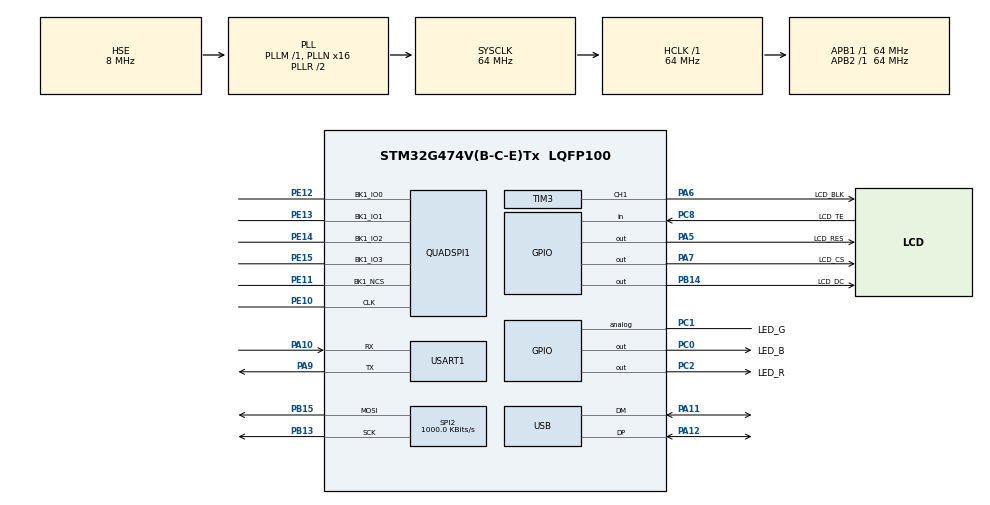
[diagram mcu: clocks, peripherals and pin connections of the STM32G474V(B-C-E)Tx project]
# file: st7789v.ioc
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Dma.Request0=SPI2_TX
Dma.SPI2_TX.0.Direction=DMA_MEMORY_TO_PERIPH
Dma.SPI2_TX.0.EventEnable=DISABLE
Dma.SPI2_TX.0.Instance=DMA1_Channel1
Dma.SPI2_TX.0.MemDataAlignment=DMA_MDATAALIGN_BYTE
Dma.SPI2_TX.0.MemInc=DMA_MINC_ENABLE
Dma.SPI2_TX.0.Mode=DMA_NORMAL
Dma.SPI2_TX.0.PeriphDataAlignment=DMA_PDATAALIGN_BYTE
Dma.SPI2_TX.0.PeriphInc=DMA_PINC_DISABLE
Dma.SPI2_TX.0.Polarity=HAL_DMAMUX_REQ_GEN_RISING
Dma.SPI2_TX.0.Priority=DMA_PRIORITY_LOW
Dma.SPI2_TX.0.RequestNumber=1
Dma.SPI2_TX.0.SignalID=NONE
Dma.SPI2_TX.0.SyncEnable=DISABLE
Dma.SPI2_TX.0.SyncPolarity=HAL_DMAMUX_SYNC_NO_EVENT
Dma.SPI2_TX.0.SyncRequestNumber=1
Dma.SPI2_TX.0.SyncSignalID=NONE
Mcu.Family=STM32G4
Mcu.Name=STM32G474V(B-C-E)Tx
Mcu.Package=LQFP100
NVIC.DMA1_Channel1_IRQn=true\:0\:0\:false\:false\:true\:false\:true\:true
NVIC.PriorityGroup=NVIC_PRIORITYGROUP_4
NVIC.USB_LP_IRQn=true\:0\:0\:false\:false\:true\:false\:true\:true
PA10.Mode=Asynchronous
PA10.Signal=USART1_RX
PA11.Mode=Device
PA11.Signal=USB_DM
PA12.Mode=Device
PA12.Signal=USB_DP
PA13.Mode=Serial_Wire
PA13.Signal=SYS_JTMS-SWDIO
PA14.Mode=Serial_Wire
PA14.Signal=SYS_JTCK-SWCLK
PA5.GPIO_Label=LCD_RES
PA5.Signal=GPIO_Output
PA6.GPIO_Label=LCD_BLK
PA6.Signal=S_TIM3_CH1
PA7.GPIO_Label=LCD_CS
PA7.Signal=GPIO_Output
PA9.Mode=Asynchronous
PA9.Signal=USART1_TX
PB13.Mode=TX_Only_Simplex_Unidirect_Master
PB13.Signal=SPI2_SCK
PB14.GPIO_Label=LCD_DC
PB14.Signal=GPIO_Output
PB15.Mode=TX_Only_Simplex_Unidirect_Master
PB15.Signal=SPI2_MOSI
PC0.GPIO_Label=LED_B
PC0.Signal=GPIO_Output
PC1.GPIO_Label=LED_G
PC1.Signal=GPIO_Analog
PC14-OSC32_IN.Mode=LSE-External-Oscillator
PC14-OSC32_IN.Signal=RCC_OSC32_IN
PC15-OSC32_OUT.Mode=LSE-External-Oscillator
PC15-OSC32_OUT.Signal=RCC_OSC32_OUT
PC2.GPIO_Label=LED_R
PC2.Signal=GPIO_Output
PC8.GPIO_Label=LCD_TE
PC8.GPIO_PuPd=GPIO_NOPULL
PC8.Signal=GPIO_Input
PE10.Mode=Single Bank 1
PE10.Signal=QUADSPI1_CLK
PE11.Mode=Single Bank 1
PE11.Signal=QUADSPI1_BK1_NCS
PE12.Mode=Single Bank 1
PE12.Signal=QUADSPI1_BK1_IO0
PE13.Mode=Single Bank 1
PE13.Signal=QUADSPI1_BK1_IO1
PE14.Mode=Single Bank 1
PE14.Signal=QUADSPI1_BK1_IO2
PE15.Mode=Single Bank 1
PE15.Signal=QUADSPI1_BK1_IO3
PF0-OSC_IN.Mode=HSE-External-Oscillator
PF0-OSC_IN.Signal=RCC_OSC_IN
PF1-OSC_OUT.Mode=HSE-External-Oscillator
PF1-OSC_OUT.Signal=RCC_OSC_OUT
ProjectManager.HeapSize=0x200
ProjectManager.StackSize=0x400
ProjectManager.TargetToolchain=STM32CubeIDE
RCC.ADC12Freq_Value=64000000
RCC.ADC345Freq_Value=64000000
RCC.AHBFreq_Value=64000000
RCC.APB1Freq_Value=64000000
RCC.APB1TimFreq_Value=64000000
RCC.APB2Freq_Value=64000000
RCC.APB2TimFreq_Value=64000000
RCC.CK48CLockSelection=RCC_USBCLKSOURCE_HSI48
RCC.CortexFreq_Value=64000000
RCC.EXTERNAL_CLOCK_VALUE=12288000
RCC.EnableCSSLSE=true
RCC.EnbaleCSS=true
RCC.HCLKFreq_Value=64000000
RCC.HSE_VALUE=8000000
RCC.HSI48_VALUE=48000000
RCC.HSI_VALUE=16000000
RCC.PLLN=16
RCC.PLLSourceVirtual=RCC_PLLSOURCE_HSE
RCC.RTCClockSelection=RCC_RTCCLKSOURCE_LSE
RCC.SYSCLKFreq_VALUE=64000000
RCC.SYSCLKSource=RCC_SYSCLKSOURCE_PLLCLK
RCC.USBFreq_Value=48000000
RCC.VCOOutputFreq_Value=128000000
SH.S_TIM3_CH1.0=TIM3_CH1,PWM Generation1 CH1
SPI2.BaudRatePrescaler=SPI_BAUDRATEPRESCALER_64
SPI2.CLKPhase=SPI_PHASE_2EDGE
SPI2.CLKPolarity=SPI_POLARITY_HIGH
SPI2.CalculateBaudRate=1000.0 KBits/s
SPI2.DataSize=SPI_DATASIZE_8BIT
SPI2.Direction=SPI_DIRECTION_2LINES
SPI2.Mode=SPI_MODE_MASTER
SPI2.VirtualType=VM_MASTER
TIM3.Channel-PWM\ Generation1\ CH1=TIM_CHANNEL_1
TIM3.PulseNoDither_1=32768 - 1
USART1.VirtualMode-Asynchronous=VM_ASYNC
USB_DEVICE.CLASS_NAME_FS=CDC
USB_DEVICE.VirtualMode=Cdc
USB_DEVICE.VirtualModeFS=Cdc_FS
VP_RTC_VS_RTC_Activate.Mode=RTC_Enabled
VP_SYS_VS_DBSignals.Mode=DisableDeadBatterySignals
VP_USB_DEVICE_VS_USB_DEVICE_CDC_FS.Mode=CDC_FS
board=custom

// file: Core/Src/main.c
/* USER CODE BEGIN Header */
/**
  ******************************************************************************
  * @file           : main.c
  * @brief          : Main program body
  ******************************************************************************
  * @attention
  *
  * Copyright (c) 2026 STMicroelectronics.
  * All rights reserved.
  *
  * This software is licensed under terms that can be found in the LICENSE file
  * in the root directory of this software component.
  * If no LICENSE file comes with this software, it is provided AS-IS.
  *
  ******************************************************************************
  */
/* USER CODE END Header */
#include "main.h"
#include "dma.h"
#include "quadspi.h"
#include "rtc.h"
#include "spi.h"
#include "tim.h"
#include "usart.h"
#include "usb_device.h"
#include "gpio.h"

void SystemClock_Config(void);
/* USER CODE BEGIN PFP */
#ifdef __GNUC__
#define PUTCHAR_PROTOTYPE int __io_putchar(int ch)
#else
#define PUTCHAR_PROTOTYPE int fputc(int ch, FILE *f)
#endif

PUTCHAR_PROTOTYPE
{
  HAL_UART_Transmit(&huart1, (uint8_t *)&ch, 1, HAL_MAX_DELAY);
  return ch;
}
/* USER CODE END PFP */

int main(void)
{

  /* USER CODE BEGIN 1 */
    // определяем где выполняется программа, и корректируем расположение таблицы векторов
    uint32_t retPCasm(void); // небольшая функция для определения где выполняется программа в FLASH или RAM
    if ((retPCasm() & 0x20000000) != 0)
    {
        SCB->VTOR = 0x20000000; /* FlagDebugInRAM=1;*/
    }
  /* USER CODE END 1 */

  /* MCU Configuration--------------------------------------------------------*/

  /* Reset of all peripherals, Initializes the Flash interface and the Systick. */
  HAL_Init();

  /* Configure the system clock */
  SystemClock_Config();

  /* Initialize all configured peripherals */
  MX_GPIO_Init();
  MX_DMA_Init();
  MX_QUADSPI1_Init();
  MX_RTC_Init();
  MX_SPI2_Init();
  MX_TIM3_Init();
  MX_USART1_UART_Init();
  MX_USB_Device_Init();
  /* USER CODE BEGIN 2 */
  void app_wrapper();
  app_wrapper();

  /* USER CODE END 2 */

  /* Infinite loop */
  while (1)
  {

  }
}

void SystemClock_Config(void)
{
  RCC_OscInitTypeDef RCC_OscInitStruct = {0};
  RCC_ClkInitTypeDef RCC_ClkInitStruct = {0};

  /** Configure the main internal regulator output voltage
  */
  HAL_PWREx_ControlVoltageScaling(PWR_REGULATOR_VOLTAGE_SCALE1);

  /** Configure LSE Drive Capability
  */
  HAL_PWR_EnableBkUpAccess();
  __HAL_RCC_LSEDRIVE_CONFIG(RCC_LSEDRIVE_LOW);

  /** Initializes the RCC Oscillators according to the specified parameters
  * in the RCC_OscInitTypeDef structure.
  */
  RCC_OscInitStruct.OscillatorType = RCC_OSCILLATORTYPE_HSI48|RCC_OSCILLATORTYPE_HSE
                              |RCC_OSCILLATORTYPE_LSE;
  RCC_OscInitStruct.HSEState = RCC_HSE_ON;
  RCC_OscInitStruct.LSEState = RCC_LSE_ON;
  RCC_OscInitStruct.HSI48State = RCC_HSI48_ON;
  RCC_OscInitStruct.PLL.PLLState = RCC_PLL_ON;
  RCC_OscInitStruct.PLL.PLLSource = RCC_PLLSOURCE_HSE;
  RCC_OscInitStruct.PLL.PLLM = RCC_PLLM_DIV1;
  RCC_OscInitStruct.PLL.PLLN = 16;
  RCC_OscInitStruct.PLL.PLLP = RCC_PLLP_DIV2;
  RCC_OscInitStruct.PLL.PLLQ = RCC_PLLQ_DIV2;
  RCC_OscInitStruct.PLL.PLLR = RCC_PLLR_DIV2;
  if (HAL_RCC_OscConfig(&RCC_OscInitStruct) != HAL_OK)
  {
    Error_Handler();
  }

  /** Initializes the CPU, AHB and APB buses clocks
  */
  RCC_ClkInitStruct.ClockType = RCC_CLOCKTYPE_HCLK|RCC_CLOCKTYPE_SYSCLK
                              |RCC_CLOCKTYPE_PCLK1|RCC_CLOCKTYPE_PCLK2;
  RCC_ClkInitStruct.SYSCLKSource = RCC_SYSCLKSOURCE_PLLCLK;
  RCC_ClkInitStruct.AHBCLKDivider = RCC_SYSCLK_DIV1;
  RCC_ClkInitStruct.APB1CLKDivider = RCC_HCLK_DIV1;
  RCC_ClkInitStruct.APB2CLKDivider = RCC_HCLK_DIV1;

  if (HAL_RCC_ClockConfig(&RCC_ClkInitStruct, FLASH_LATENCY_2) != HAL_OK)
  {
    Error_Handler();
  }

  /** Enables the Clock Security System
  */
  HAL_RCC_EnableCSS();

  /** Enables the Clock Security System
  */
  HAL_RCC_EnableLSECSS();
}

void Error_Handler(void)
{
  __disable_irq();
  while (1)
  {
  }
}
